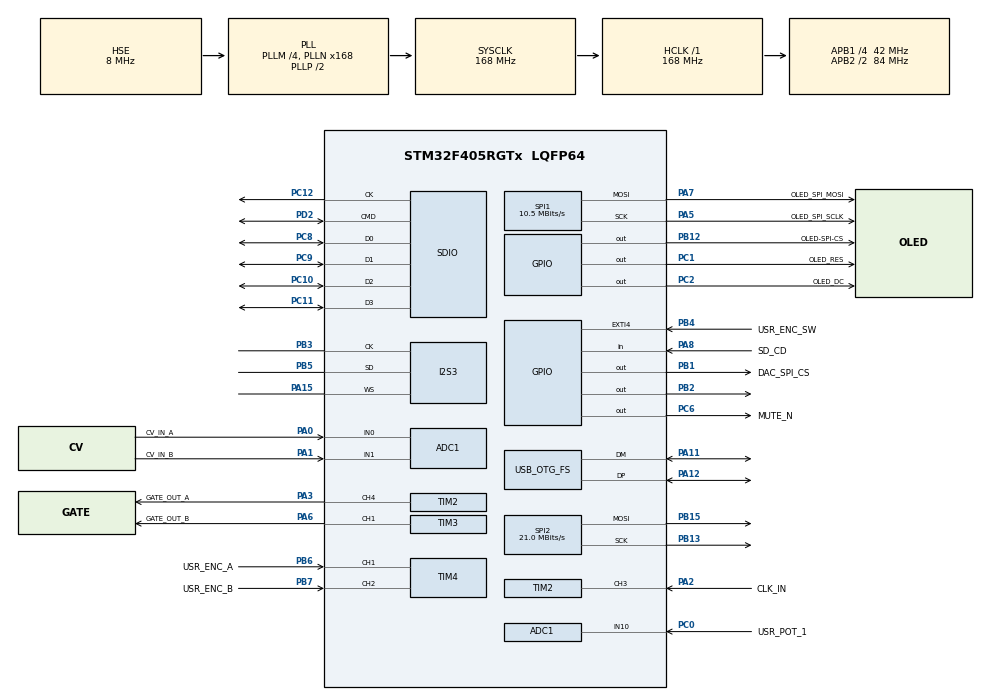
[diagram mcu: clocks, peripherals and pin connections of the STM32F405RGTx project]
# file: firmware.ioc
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ADC1.Channel-0\#ChannelRegularConversion=ADC_CHANNEL_0
ADC1.Channel-1\#ChannelRegularConversion=ADC_CHANNEL_1
ADC1.Channel-2\#ChannelRegularConversion=ADC_CHANNEL_10
ADC1.NbrOfConversion=3
ADC1.NbrOfConversionFlag=1
ADC1.Rank-0\#ChannelRegularConversion=1
ADC1.Rank-1\#ChannelRegularConversion=2
ADC1.Rank-2\#ChannelRegularConversion=3
ADC1.SamplingTime-0\#ChannelRegularConversion=ADC_SAMPLETIME_3CYCLES
ADC1.SamplingTime-1\#ChannelRegularConversion=ADC_SAMPLETIME_3CYCLES
ADC1.SamplingTime-2\#ChannelRegularConversion=ADC_SAMPLETIME_3CYCLES
ADC1.master=1
I2S3.AudioFreq=I2S_AUDIOFREQ_192K
I2S3.CPOL=I2S_CPOL_LOW
I2S3.DataFormat=I2S_DATAFORMAT_32B
I2S3.ErrorAudioFreq=-2.34 %
I2S3.FullDuplexMode=I2S_FULLDUPLEXMODE_DISABLE
I2S3.Instance=SPI$Index
I2S3.RealAudioFreq=187.5 KHz
I2S3.VirtualMode=I2S_MODE_MASTER
Mcu.Family=STM32F4
Mcu.Name=STM32F405RGTx
Mcu.Package=LQFP64
NVIC.EXTI4_IRQn=true\:0\:0\:false\:false\:true\:true\:true\:true
NVIC.OTG_FS_IRQn=true\:0\:0\:false\:false\:true\:false\:true\:true
NVIC.PriorityGroup=NVIC_PRIORITYGROUP_4
PA0-WKUP.GPIO_Label=CV_IN_A
PA0-WKUP.Signal=ADCx_IN0
PA1.GPIO_Label=CV_IN_B
PA1.Signal=ADCx_IN1
PA11.Mode=Device_Only
PA11.Signal=USB_OTG_FS_DM
PA12.Mode=Device_Only
PA12.Signal=USB_OTG_FS_DP
PA15.Mode=Half_Duplex_Master
PA15.Signal=I2S3_WS
PA2.GPIO_Label=CLK_IN
PA2.Signal=S_TIM2_CH3
PA3.GPIO_Label=GATE_OUT_A
PA3.Signal=S_TIM2_CH4
PA5.GPIO_Label=OLED_SPI_SCLK
PA5.Mode=TX_Only_Simplex_Unidirect_Master
PA5.Signal=SPI1_SCK
PA6.GPIO_Label=GATE_OUT_B
PA6.Signal=S_TIM3_CH1
PA7.GPIO_Label=OLED_SPI_MOSI
PA7.Mode=TX_Only_Simplex_Unidirect_Master
PA7.Signal=SPI1_MOSI
PA8.GPIO_Label=SD_CD
PA8.GPIO_PuPd=GPIO_PULLUP
PA8.Signal=GPIO_Input
PB1.GPIO_Label=DAC_SPI_CS
PB1.PinState=GPIO_PIN_SET
PB1.Signal=GPIO_Output
PB12.GPIO_Label=OLED-SPI-CS
PB12.GPIO_Speed=GPIO_SPEED_FREQ_HIGH
PB12.PinState=GPIO_PIN_SET
PB12.Signal=GPIO_Output
PB13.Mode=TX_Only_Simplex_Unidirect_Master
PB13.Signal=SPI2_SCK
PB15.Mode=TX_Only_Simplex_Unidirect_Master
PB15.Signal=SPI2_MOSI
PB2.Signal=GPIO_Output
PB3.GPIO_Speed=GPIO_SPEED_FREQ_VERY_HIGH
PB3.Mode=Half_Duplex_Master
PB3.Signal=I2S3_CK
PB4.GPIO_Label=USR_ENC_SW
PB4.GPIO_ModeDefaultEXTI=GPIO_MODE_IT_FALLING
PB4.GPIO_PuPd=GPIO_PULLUP
PB4.Signal=GPXTI4
PB5.GPIO_Speed=GPIO_SPEED_FREQ_VERY_HIGH
PB5.Mode=Half_Duplex_Master
PB5.Signal=I2S3_SD
PB6.GPIO_Label=USR_ENC_A
PB6.GPIO_PuPd=GPIO_PULLUP
PB6.Signal=S_TIM4_CH1
PB7.GPIO_Label=USR_ENC_B
PB7.GPIO_PuPd=GPIO_PULLUP
PB7.Signal=S_TIM4_CH2
PC0.GPIO_Label=USR_POT_1
PC0.Signal=ADCx_IN10
PC1.GPIO_Label=OLED_RES
PC1.GPIO_PuPd=GPIO_NOPULL
PC1.GPIO_Speed=GPIO_SPEED_FREQ_HIGH
PC1.PinState=GPIO_PIN_SET
PC1.Signal=GPIO_Output
PC10.Mode=SD_4_bits_Wide_bus
PC10.Signal=SDIO_D2
PC11.Mode=SD_4_bits_Wide_bus
PC11.Signal=SDIO_D3
PC12.Mode=SD_4_bits_Wide_bus
PC12.Signal=SDIO_CK
PC2.GPIO_Label=OLED_DC
PC2.GPIO_Speed=GPIO_SPEED_FREQ_HIGH
PC2.PinState=GPIO_PIN_SET
PC2.Signal=GPIO_Output
PC6.GPIO_Label=MUTE_N
PC6.PinState=GPIO_PIN_SET
PC6.Signal=GPIO_Output
PC8.Mode=SD_4_bits_Wide_bus
PC8.Signal=SDIO_D0
PC9.Mode=SD_4_bits_Wide_bus
PC9.Signal=SDIO_D1
PD2.Mode=SD_4_bits_Wide_bus
PD2.Signal=SDIO_CMD
PH0-OSC_IN.Mode=HSE-External-Oscillator
PH0-OSC_IN.Signal=RCC_OSC_IN
PH1-OSC_OUT.Mode=HSE-External-Oscillator
PH1-OSC_OUT.Signal=RCC_OSC_OUT
ProjectManager.HeapSize=0x200
ProjectManager.StackSize=0x400
ProjectManager.TargetToolchain=CMake
RCC.48MHZClocksFreq_Value=48000000
RCC.AHBFreq_Value=168000000
RCC.APB1CLKDivider=RCC_HCLK_DIV4
RCC.APB1Freq_Value=42000000
RCC.APB1TimFreq_Value=84000000
RCC.APB2CLKDivider=RCC_HCLK_DIV2
RCC.APB2Freq_Value=84000000
RCC.APB2TimFreq_Value=168000000
RCC.CortexFreq_Value=168000000
RCC.HCLKFreq_Value=168000000
RCC.HSE_VALUE=8000000
RCC.HSI_VALUE=16000000
RCC.LSE_VALUE=32768
RCC.PLLM=4
RCC.PLLN=168
RCC.PLLQ=7
RCC.SYSCLKFreq_VALUE=168000000
RCC.SYSCLKSource=RCC_SYSCLKSOURCE_PLLCLK
RCC.VCOOutputFreq_Value=336000000
SH.ADCx_IN0.0=ADC1_IN0,IN0
SH.ADCx_IN1.0=ADC1_IN1,IN1
SH.ADCx_IN10.0=ADC1_IN10,IN10
SH.S_TIM2_CH3.0=TIM2_CH3,Input_Capture3_from_TI3
SH.S_TIM2_CH4.0=TIM2_CH4,Output Compare4 CH4
SH.S_TIM3_CH1.0=TIM3_CH1,PWM Generation1 CH1
SH.S_TIM4_CH1.0=TIM4_CH1,Encoder_Interface
SH.S_TIM4_CH2.0=TIM4_CH2,Encoder_Interface
SPI1.BaudRatePrescaler=SPI_BAUDRATEPRESCALER_8
SPI1.CalculateBaudRate=10.5 MBits/s
SPI1.Direction=SPI_DIRECTION_2LINES
SPI1.Mode=SPI_MODE_MASTER
SPI1.VirtualType=VM_MASTER
SPI2.CLKPhase=SPI_PHASE_2EDGE
SPI2.CalculateBaudRate=21.0 MBits/s
SPI2.Direction=SPI_DIRECTION_2LINES
SPI2.Mode=SPI_MODE_MASTER
SPI2.VirtualType=VM_MASTER
TIM2.Channel-Input_Capture3_from_TI3=TIM_CHANNEL_3
TIM2.Channel-Output\ Compare4\ CH4=TIM_CHANNEL_4
TIM3.Channel-PWM\ Generation1\ CH1=TIM_CHANNEL_1
TIM4.EncoderMode=TIM_ENCODERMODE_TI12
TIM4.IC1Filter=4
TIM4.IC2Filter=4
USB_DEVICE.CLASS_NAME_FS=CDC
USB_DEVICE.VirtualMode-CDC_FS=Cdc
USB_DEVICE.VirtualModeFS=Cdc_FS
USB_OTG_FS.VirtualMode=Device_Only
VP_USB_DEVICE_VS_USB_DEVICE_CDC_FS.Mode=CDC_FS
board=custom

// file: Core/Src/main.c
/* USER CODE BEGIN Header */
/**
  ******************************************************************************
  * @file           : main.c
  * @brief          : Main program body
  ******************************************************************************
  * @attention
  *
  * Copyright (c) 2026 STMicroelectronics.
  * All rights reserved.
  *
  * This software is licensed under terms that can be found in the LICENSE file
  * in the root directory of this software component.
  * If no LICENSE file comes with this software, it is provided AS-IS.
  *
  ******************************************************************************
  */
/* USER CODE END Header */
#include "main.h"
#include "usb_device.h"

/* USER CODE BEGIN Includes */
#include <stdio.h>
#include "usbd_cdc_if.h"
#include "test_console.h"
#include "encoder.h"
/* USER CODE END Includes */

ADC_HandleTypeDef hadc1;

I2S_HandleTypeDef hi2s3;
DMA_HandleTypeDef hdma_spi3_tx;

SD_HandleTypeDef hsd;

SPI_HandleTypeDef hspi1;
SPI_HandleTypeDef hspi2;

TIM_HandleTypeDef htim2;
TIM_HandleTypeDef htim3;
TIM_HandleTypeDef htim4;

void SystemClock_Config(void);
static void MX_GPIO_Init(void);
static void MX_DMA_Init(void);
static void MX_SPI1_Init(void);
static void MX_TIM4_Init(void);
static void MX_I2S3_Init(void);
static void MX_SDIO_SD_Init(void);
static void MX_ADC1_Init(void);
static void MX_SPI2_Init(void);
static void MX_TIM2_Init(void);
static void MX_TIM3_Init(void);

/* USER CODE BEGIN 0 */
int _write(int file, char *ptr, int len)
{
    CDC_Transmit_FS((uint8_t*)ptr, len);
    return len;
}
/* USER CODE END 0 */

int main(void)
{

  /* MCU Configuration--------------------------------------------------------*/

  /* Reset of all peripherals, Initializes the Flash interface and the Systick. */
  HAL_Init();

  /* Configure the system clock */
  SystemClock_Config();

  /* Initialize all configured peripherals */
  MX_GPIO_Init();
  MX_DMA_Init();
  MX_USB_DEVICE_Init();
  MX_SPI1_Init();
  MX_TIM4_Init();
  MX_I2S3_Init();
  /* SD card detect is NC switch: LOW=no card, HIGH=card inserted */
  if (HAL_GPIO_ReadPin(SD_CD_GPIO_Port, SD_CD_Pin) == GPIO_PIN_SET) {
    MX_SDIO_SD_Init();
  }
  MX_ADC1_Init();
  MX_SPI2_Init();
  MX_TIM2_Init();
  MX_TIM3_Init();
  /* USER CODE BEGIN 2 */
  HAL_Delay(1000);
  printf("USB ready\r\n");

  console_init();
  /* USER CODE END 2 */

  /* Infinite loop */
  while (1)
  {

    /* USER CODE BEGIN 3 */
    console_poll();
  }
  /* USER CODE END 3 */
}

void SystemClock_Config(void)
{
  RCC_OscInitTypeDef RCC_OscInitStruct = {0};
  RCC_ClkInitTypeDef RCC_ClkInitStruct = {0};

  /** Configure the main internal regulator output voltage
  */
  __HAL_RCC_PWR_CLK_ENABLE();
  __HAL_PWR_VOLTAGESCALING_CONFIG(PWR_REGULATOR_VOLTAGE_SCALE1);

  /** Initializes the RCC Oscillators according to the specified parameters
  * in the RCC_OscInitTypeDef structure.
  */
  RCC_OscInitStruct.OscillatorType = RCC_OSCILLATORTYPE_HSE;
  RCC_OscInitStruct.HSEState = RCC_HSE_ON;
  RCC_OscInitStruct.PLL.PLLState = RCC_PLL_ON;
  RCC_OscInitStruct.PLL.PLLSource = RCC_PLLSOURCE_HSE;
  RCC_OscInitStruct.PLL.PLLM = 4;
  RCC_OscInitStruct.PLL.PLLN = 168;
  RCC_OscInitStruct.PLL.PLLP = RCC_PLLP_DIV2;
  RCC_OscInitStruct.PLL.PLLQ = 7;
  if (HAL_RCC_OscConfig(&RCC_OscInitStruct) != HAL_OK)
  {
    Error_Handler();
  }

  /** Initializes the CPU, AHB and APB buses clocks
  */
  RCC_ClkInitStruct.ClockType = RCC_CLOCKTYPE_HCLK|RCC_CLOCKTYPE_SYSCLK
                              |RCC_CLOCKTYPE_PCLK1|RCC_CLOCKTYPE_PCLK2;
  RCC_ClkInitStruct.SYSCLKSource = RCC_SYSCLKSOURCE_PLLCLK;
  RCC_ClkInitStruct.AHBCLKDivider = RCC_SYSCLK_DIV1;
  RCC_ClkInitStruct.APB1CLKDivider = RCC_HCLK_DIV4;
  RCC_ClkInitStruct.APB2CLKDivider = RCC_HCLK_DIV2;

  if (HAL_RCC_ClockConfig(&RCC_ClkInitStruct, FLASH_LATENCY_5) != HAL_OK)
  {
    Error_Handler();
  }
}

static void MX_ADC1_Init(void)
{

  ADC_ChannelConfTypeDef sConfig = {0};

  /** Configure the global features of the ADC (Clock, Resolution, Data Alignment and number of conversion)
  */
  hadc1.Instance = ADC1;
  hadc1.Init.ClockPrescaler = ADC_CLOCK_SYNC_PCLK_DIV4;
  hadc1.Init.Resolution = ADC_RESOLUTION_12B;
  hadc1.Init.ScanConvMode = ENABLE;
  hadc1.Init.ContinuousConvMode = DISABLE;
  hadc1.Init.DiscontinuousConvMode = DISABLE;
  hadc1.Init.ExternalTrigConvEdge = ADC_EXTERNALTRIGCONVEDGE_NONE;
  hadc1.Init.ExternalTrigConv = ADC_SOFTWARE_START;
  hadc1.Init.DataAlign = ADC_DATAALIGN_RIGHT;
  hadc1.Init.NbrOfConversion = 3;
  hadc1.Init.DMAContinuousRequests = DISABLE;
  hadc1.Init.EOCSelection = ADC_EOC_SINGLE_CONV;
  if (HAL_ADC_Init(&hadc1) != HAL_OK)
  {
    Error_Handler();
  }

  /** Configure for the selected ADC regular channel its corresponding rank in the sequencer and its sample time.
  */
  sConfig.Channel = ADC_CHANNEL_0;
  sConfig.Rank = 1;
  /* 56 cycles per cv-input.md §5 (was 3 — too short for the ~1 kOhm source;
   * also gives the polled scan loop ~3.2 us/conversion of margin to read each
   * rank before the next completes). Reused for ranks 2 and 3 below. */
  sConfig.SamplingTime = ADC_SAMPLETIME_56CYCLES;
  if (HAL_ADC_ConfigChannel(&hadc1, &sConfig) != HAL_OK)
  {
    Error_Handler();
  }

  /** Configure for the selected ADC regular channel its corresponding rank in the sequencer and its sample time.
  */
  sConfig.Channel = ADC_CHANNEL_1;
  sConfig.Rank = 2;
  if (HAL_ADC_ConfigChannel(&hadc1, &sConfig) != HAL_OK)
  {
    Error_Handler();
  }

  /** Configure for the selected ADC regular channel its corresponding rank in the sequencer and its sample time.
  */
  sConfig.Channel = ADC_CHANNEL_10;
  sConfig.Rank = 3;
  if (HAL_ADC_ConfigChannel(&hadc1, &sConfig) != HAL_OK)
  {
    Error_Handler();
  }

}

static void MX_DMA_Init(void)
{
  /* DMA controller clock enable */
  __HAL_RCC_DMA1_CLK_ENABLE();

  /* DMA interrupt init: SPI3_TX = DMA1_Stream5. Low priority so the USB CDC
   * and SysTick IRQs always preempt the (sinf-heavy) audio refill callback. */
  HAL_NVIC_SetPriority(DMA1_Stream5_IRQn, 8, 0);
  HAL_NVIC_EnableIRQ(DMA1_Stream5_IRQn);
}

static void MX_I2S3_Init(void)
{

  hi2s3.Instance = SPI3;
  hi2s3.Init.Mode = I2S_MODE_MASTER_TX;
  hi2s3.Init.Standard = I2S_STANDARD_PHILIPS;
  hi2s3.Init.DataFormat = I2S_DATAFORMAT_32B;
  hi2s3.Init.MCLKOutput = I2S_MCLKOUTPUT_DISABLE;
  hi2s3.Init.AudioFreq = I2S_AUDIOFREQ_192K;
  hi2s3.Init.CPOL = I2S_CPOL_LOW;
  hi2s3.Init.ClockSource = I2S_CLOCK_PLL;
  hi2s3.Init.FullDuplexMode = I2S_FULLDUPLEXMODE_DISABLE;
  if (HAL_I2S_Init(&hi2s3) != HAL_OK)
  {
    Error_Handler();
  }

}

static void MX_SDIO_SD_Init(void)
{

  hsd.Instance = SDIO;
  hsd.Init.ClockEdge = SDIO_CLOCK_EDGE_RISING;
  hsd.Init.ClockBypass = SDIO_CLOCK_BYPASS_DISABLE;
  hsd.Init.ClockPowerSave = SDIO_CLOCK_POWER_SAVE_DISABLE;
  hsd.Init.BusWide = SDIO_BUS_WIDE_1B;
  hsd.Init.HardwareFlowControl = SDIO_HARDWARE_FLOW_CONTROL_DISABLE;
  hsd.Init.ClockDiv = 0;
  if (HAL_SD_Init(&hsd) != HAL_OK)
  {
    Error_Handler();
  }
  if (HAL_SD_ConfigWideBusOperation(&hsd, SDIO_BUS_WIDE_4B) != HAL_OK)
  {
    Error_Handler();
  }

}

static void MX_SPI1_Init(void)
{

  /* SPI1 parameter configuration*/
  hspi1.Instance = SPI1;
  hspi1.Init.Mode = SPI_MODE_MASTER;
  hspi1.Init.Direction = SPI_DIRECTION_2LINES;
  hspi1.Init.DataSize = SPI_DATASIZE_8BIT;
  hspi1.Init.CLKPolarity = SPI_POLARITY_LOW;
  hspi1.Init.CLKPhase = SPI_PHASE_1EDGE;
  hspi1.Init.NSS = SPI_NSS_SOFT;
  hspi1.Init.BaudRatePrescaler = SPI_BAUDRATEPRESCALER_8;
  hspi1.Init.FirstBit = SPI_FIRSTBIT_MSB;
  hspi1.Init.TIMode = SPI_TIMODE_DISABLE;
  hspi1.Init.CRCCalculation = SPI_CRCCALCULATION_DISABLE;
  hspi1.Init.CRCPolynomial = 10;
  if (HAL_SPI_Init(&hspi1) != HAL_OK)
  {
    Error_Handler();
  }

}

static void MX_SPI2_Init(void)
{

  /* SPI2 parameter configuration*/
  hspi2.Instance = SPI2;
  hspi2.Init.Mode = SPI_MODE_MASTER;
  hspi2.Init.Direction = SPI_DIRECTION_2LINES;
  hspi2.Init.DataSize = SPI_DATASIZE_8BIT;
  hspi2.Init.CLKPolarity = SPI_POLARITY_LOW;
  hspi2.Init.CLKPhase = SPI_PHASE_2EDGE;
  hspi2.Init.NSS = SPI_NSS_SOFT;
  hspi2.Init.BaudRatePrescaler = SPI_BAUDRATEPRESCALER_2;
  hspi2.Init.FirstBit = SPI_FIRSTBIT_MSB;
  hspi2.Init.TIMode = SPI_TIMODE_DISABLE;
  hspi2.Init.CRCCalculation = SPI_CRCCALCULATION_DISABLE;
  hspi2.Init.CRCPolynomial = 10;
  if (HAL_SPI_Init(&hspi2) != HAL_OK)
  {
    Error_Handler();
  }

}

static void MX_TIM2_Init(void)
{

  TIM_MasterConfigTypeDef sMasterConfig = {0};
  TIM_IC_InitTypeDef sConfigIC = {0};
  TIM_OC_InitTypeDef sConfigOC = {0};

  htim2.Instance = TIM2;
  htim2.Init.Prescaler = 0;
  htim2.Init.CounterMode = TIM_COUNTERMODE_UP;
  htim2.Init.Period = 4294967295;
  htim2.Init.ClockDivision = TIM_CLOCKDIVISION_DIV1;
  htim2.Init.AutoReloadPreload = TIM_AUTORELOAD_PRELOAD_DISABLE;
  if (HAL_TIM_IC_Init(&htim2) != HAL_OK)
  {
    Error_Handler();
  }
  if (HAL_TIM_OC_Init(&htim2) != HAL_OK)
  {
    Error_Handler();
  }
  sMasterConfig.MasterOutputTrigger = TIM_TRGO_RESET;
  sMasterConfig.MasterSlaveMode = TIM_MASTERSLAVEMODE_DISABLE;
  if (HAL_TIMEx_MasterConfigSynchronization(&htim2, &sMasterConfig) != HAL_OK)
  {
    Error_Handler();
  }
  sConfigIC.ICPolarity = TIM_INPUTCHANNELPOLARITY_RISING;
  sConfigIC.ICSelection = TIM_ICSELECTION_DIRECTTI;
  sConfigIC.ICPrescaler = TIM_ICPSC_DIV1;
  sConfigIC.ICFilter = 4;  /* fDTS/2, N=6 debounce (clock-input.md §5) — rejects
                            * sub-us edge ringing on the CLK-IN capture */
  if (HAL_TIM_IC_ConfigChannel(&htim2, &sConfigIC, TIM_CHANNEL_3) != HAL_OK)
  {
    Error_Handler();
  }
  sConfigOC.OCMode = TIM_OCMODE_TIMING;
  sConfigOC.Pulse = 0;
  sConfigOC.OCPolarity = TIM_OCPOLARITY_HIGH;
  sConfigOC.OCFastMode = TIM_OCFAST_DISABLE;
  if (HAL_TIM_OC_ConfigChannel(&htim2, &sConfigOC, TIM_CHANNEL_4) != HAL_OK)
  {
    Error_Handler();
  }
  HAL_TIM_MspPostInit(&htim2);

}

static void MX_TIM3_Init(void)
{

  TIM_MasterConfigTypeDef sMasterConfig = {0};
  TIM_OC_InitTypeDef sConfigOC = {0};

  htim3.Instance = TIM3;
  htim3.Init.Prescaler = 0;
  htim3.Init.CounterMode = TIM_COUNTERMODE_UP;
  htim3.Init.Period = 65535;
  htim3.Init.ClockDivision = TIM_CLOCKDIVISION_DIV1;
  htim3.Init.AutoReloadPreload = TIM_AUTORELOAD_PRELOAD_DISABLE;
  if (HAL_TIM_PWM_Init(&htim3) != HAL_OK)
  {
    Error_Handler();
  }
  sMasterConfig.MasterOutputTrigger = TIM_TRGO_RESET;
  sMasterConfig.MasterSlaveMode = TIM_MASTERSLAVEMODE_DISABLE;
  if (HAL_TIMEx_MasterConfigSynchronization(&htim3, &sMasterConfig) != HAL_OK)
  {
    Error_Handler();
  }
  sConfigOC.OCMode = TIM_OCMODE_PWM1;
  sConfigOC.Pulse = 0;
  sConfigOC.OCPolarity = TIM_OCPOLARITY_HIGH;
  sConfigOC.OCFastMode = TIM_OCFAST_DISABLE;
  if (HAL_TIM_PWM_ConfigChannel(&htim3, &sConfigOC, TIM_CHANNEL_1) != HAL_OK)
  {
    Error_Handler();
  }
  HAL_TIM_MspPostInit(&htim3);

}

static void MX_TIM4_Init(void)
{

  TIM_Encoder_InitTypeDef sConfig = {0};
  TIM_MasterConfigTypeDef sMasterConfig = {0};

  htim4.Instance = TIM4;
  htim4.Init.Prescaler = 0;
  htim4.Init.CounterMode = TIM_COUNTERMODE_UP;
  htim4.Init.Period = 65535;
  htim4.Init.ClockDivision = TIM_CLOCKDIVISION_DIV1;
  htim4.Init.AutoReloadPreload = TIM_AUTORELOAD_PRELOAD_DISABLE;
  sConfig.EncoderMode = TIM_ENCODERMODE_TI12;
  sConfig.IC1Polarity = TIM_ICPOLARITY_RISING;
  sConfig.IC1Selection = TIM_ICSELECTION_DIRECTTI;
  sConfig.IC1Prescaler = TIM_ICPSC_DIV1;
  sConfig.IC1Filter = 4;
  sConfig.IC2Polarity = TIM_ICPOLARITY_RISING;
  sConfig.IC2Selection = TIM_ICSELECTION_DIRECTTI;
  sConfig.IC2Prescaler = TIM_ICPSC_DIV1;
  sConfig.IC2Filter = 4;
  if (HAL_TIM_Encoder_Init(&htim4, &sConfig) != HAL_OK)
  {
    Error_Handler();
  }
  sMasterConfig.MasterOutputTrigger = TIM_TRGO_RESET;
  sMasterConfig.MasterSlaveMode = TIM_MASTERSLAVEMODE_DISABLE;
  if (HAL_TIMEx_MasterConfigSynchronization(&htim4, &sMasterConfig) != HAL_OK)
  {
    Error_Handler();
  }

}

static void MX_GPIO_Init(void)
{
  GPIO_InitTypeDef GPIO_InitStruct = {0};

  /* GPIO Ports Clock Enable */
  __HAL_RCC_GPIOH_CLK_ENABLE();
  __HAL_RCC_GPIOC_CLK_ENABLE();
  __HAL_RCC_GPIOA_CLK_ENABLE();
  __HAL_RCC_GPIOB_CLK_ENABLE();
  __HAL_RCC_GPIOD_CLK_ENABLE();

  /*Configure GPIO pin Output Level */
  HAL_GPIO_WritePin(GPIOC, OLED_RES_Pin|OLED_DC_Pin|MUTE_N_Pin, GPIO_PIN_SET);

  /*Configure GPIO pin Output Level */
  HAL_GPIO_WritePin(GPIOB, DAC_SPI_CS_Pin|OLED_SPI_CS_Pin, GPIO_PIN_SET);

  /*Configure GPIO pin Output Level */
  HAL_GPIO_WritePin(GPIOB, GPIO_PIN_2, GPIO_PIN_RESET);

  /*Configure GPIO pins : OLED_RES_Pin OLED_DC_Pin */
  GPIO_InitStruct.Pin = OLED_RES_Pin|OLED_DC_Pin;
  GPIO_InitStruct.Mode = GPIO_MODE_OUTPUT_PP;
  GPIO_InitStruct.Pull = GPIO_NOPULL;
  GPIO_InitStruct.Speed = GPIO_SPEED_FREQ_HIGH;
  HAL_GPIO_Init(GPIOC, &GPIO_InitStruct);

  /*Configure GPIO pins : DAC_SPI_CS_Pin PB2 */
  GPIO_InitStruct.Pin = DAC_SPI_CS_Pin|GPIO_PIN_2;
  GPIO_InitStruct.Mode = GPIO_MODE_OUTPUT_PP;
  GPIO_InitStruct.Pull = GPIO_NOPULL;
  GPIO_InitStruct.Speed = GPIO_SPEED_FREQ_LOW;
  HAL_GPIO_Init(GPIOB, &GPIO_InitStruct);

  /*Configure GPIO pin : OLED_SPI_CS_Pin */
  GPIO_InitStruct.Pin = OLED_SPI_CS_Pin;
  GPIO_InitStruct.Mode = GPIO_MODE_OUTPUT_PP;
  GPIO_InitStruct.Pull = GPIO_NOPULL;
  GPIO_InitStruct.Speed = GPIO_SPEED_FREQ_HIGH;
  HAL_GPIO_Init(OLED_SPI_CS_GPIO_Port, &GPIO_InitStruct);

  /*Configure GPIO pin : MUTE_N_Pin */
  GPIO_InitStruct.Pin = MUTE_N_Pin;
  GPIO_InitStruct.Mode = GPIO_MODE_OUTPUT_PP;
  GPIO_InitStruct.Pull = GPIO_NOPULL;
  GPIO_InitStruct.Speed = GPIO_SPEED_FREQ_LOW;
  HAL_GPIO_Init(MUTE_N_GPIO_Port, &GPIO_InitStruct);

  /*Configure GPIO pin : SD_CD_Pin */
  GPIO_InitStruct.Pin = SD_CD_Pin;
  GPIO_InitStruct.Mode = GPIO_MODE_INPUT;
  GPIO_InitStruct.Pull = GPIO_PULLUP;
  HAL_GPIO_Init(SD_CD_GPIO_Port, &GPIO_InitStruct);

  /*Configure GPIO pin : USR_ENC_SW_Pin */
  GPIO_InitStruct.Pin = USR_ENC_SW_Pin;
  GPIO_InitStruct.Mode = GPIO_MODE_IT_FALLING;
  GPIO_InitStruct.Pull = GPIO_PULLUP;
  HAL_GPIO_Init(USR_ENC_SW_GPIO_Port, &GPIO_InitStruct);

  /* EXTI interrupt init*/
  HAL_NVIC_SetPriority(EXTI4_IRQn, 0, 0);
  HAL_NVIC_EnableIRQ(EXTI4_IRQn);

}

/* USER CODE BEGIN 4 */
void HAL_GPIO_EXTI_Callback(uint16_t GPIO_Pin)
{
  if (GPIO_Pin == USR_ENC_SW_Pin) {
    encoder_button_isr();
  }
}
/* USER CODE END 4 */

void Error_Handler(void)
{
  __disable_irq();
  while (1)
  {
  }
}
